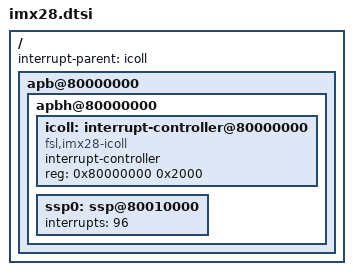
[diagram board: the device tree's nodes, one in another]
// interrupt example

/ {
	interrupt-parent = <&icoll>;
	apb@80000000 {
		apbh@80000000 {
			icoll: interrupt-controller@80000000 {
				compatible = "fsl,imx28-icoll", "fsl,icoll";
				interrupt-controller;
				#interrupt-cells = <1>;
				reg = <0x80000000 0x2000>;
			};

			ssp0: ssp@80010000 {
				interrupts = <96>;
			}
		};
	}
}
